# STM32G553 register map
File version: 2.0.0
CPU: CM33 r0p4, little endian, MPU, FPU, 4 interrupt priority bits
Registers are 32-bit, read-write, reset 0x0 unless marked. A register's access mark holds for its fields unless they carry their own. Offsets are from the block's base; [hi:lo] are bit positions.

## PKA — PKA register blank and RAM
Base 0x46008000
Same registers: PKA_S 0x56008000
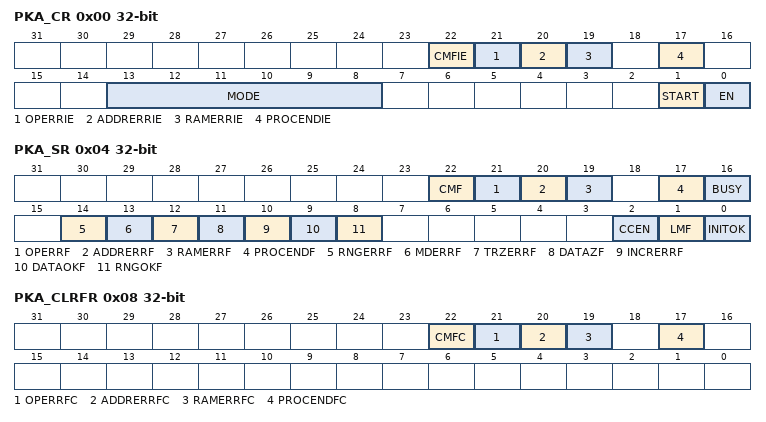
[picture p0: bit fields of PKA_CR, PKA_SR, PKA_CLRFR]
0x00 PKA_CR — PKA control register
  [22] CMFIE — Chaining mode flags interrupt enable
    0=No interrupt is generated when any flag in bits 8 to 15 is set in PKA_SR; 1=An interrupt is generated when any flag in bits 8 to 15 is set in PKA_SR
  [21] OPERRIE — Operation error interrupt enable
    0=No interrupt is generated when OPERRF flag is set in PKA_SR; 1=An interrupt is generated when OPERRF flag is set in PKA_SR
  [20] ADDRERRIE — Address error interrupt enable
    0=No interrupt is generated when ADDRERRF flag is set in PKA_SR; 1=An interrupt is generated when ADDRERRF flag is set in PKA_SR
  [19] RAMERRIE — RAM error interrupt enable
    0=No interrupt is generated when RAMERRF flag is set in PKA_SR; 1=An interrupt is generated when RAMERRF flag is set in PKA_SR
  [17] PROCENDIE — End of operation interrupt enable
    0=No interrupt is generated when PROCENDF flag is set in PKA_SR; 1=An interrupt is generated when PROCENDF flag is set in PKA_SR
  [13:8] MODE — PKA operation code
    0=Montgomery parameter computation then modular exponentiation; 1=Montgomery parameter computation only; 2=Modular exponentiation only (Montgomery parameter must be loaded first); 3=Modular exponentiation (protected, used when manipulating secrets); 32=Montgomery parameter computation then ECC scalar multiplication (protected); 36=ECDSA sign (protected); 38=ECDSA verification; 40=Point on elliptic curve Fp check; 7=RSA CRT exponentiation; 8=Modular inversion; 9=Arithmetic addition; 10=Arithmetic subtraction; 11=Arithmetic multiplication; 12=Arithmetic comparison; 13=Modular reduction; 14=Modular addition; 15=Modular subtraction; 16=Montgomery multiplication; 35=ECC complete addition; 39=ECC double base ladder; 47=ECC projective to affine
  [1] START — start the operation
  [0] EN — PKA enable
    0=Disable PKA; 1=Enable PKA; PKA becomes functional when INITOK is set by hardware in PKA_SR
0x04 PKA_SR ro — PKA status register
  [22] CMF — Chaining mode flags
    0=No chaining mode events; 1=Ongoing chaining mode sequence triggered at least one flag status in bits 8 to 14 of this register
  [21] OPERRF — Operation error flag
    0=No event error; 1=An illegal or unknown operation has been selected in PKA_CR register
  [20] ADDRERRF — Address error flag
    0=No address error; 1=Address access is out of range (unmapped address)
  [19] RAMERRF — PKA RAM error flag
    0=No PKA RAM access error; 1=An AHB access to the PKA RAM occurred while the PKA core was computing and using its internal RAM (AHB PKA_RAM access are not allowed while PKA operation is in progress)
  [17] PROCENDF — PKA end of operation flag
    0=Operation in progress; 1=PKA operation is completed. This flag is set when the BUSY bit is deasserted.
  [16] BUSY — Busy flag
    0=No operation is in progress (default); 1=An operation is in progress
  [14] RNGERRF — RNG error flag
    0=No random number drawn from RNG, or generated ECC private key is NIST compliant; 1=Random number drawn from RNG did not pass NIST key pair generation by testing candidates equivalent algorithm (see FIPS 186-4 annex B.4.2). The last chaining operation must be restarted, otherwise the selected PKA operation remains unusable.
  [13] MDERRF — Mode error flag
    0=No mode error; 1=The value written in MODE[5:0] of PKA_CR registers is different from the expected value corresponding to the CCOP mode selected in the CCB peripheral. Refer to Section30.4.7 for details.
  [12] TRZERRF — Trailing zeroes error flag
    0=No trailing 0s error; 1=Clear-text coming from CPU, or decrypted data coming from SAES does not have the required trailing 0s
  [11] DATAZF — Data zeroed error flag
  [10] INCRERRF — Increment error flag
    0=No increment error; 1=During the reading or writing of protected parameters from or to the PKA RAM, the application did not properly incremented the address. Refer to Section30.4.7 for details.
  [9] DATAOKF — Data OK flag
    0=Data not OK (if applicable), otherwise no event; 1=Sequential writes or reads to or from the PKA RAM successfully transfered the expected amount of data from or to SAES. Alternatively, the CPU wrote the correct amount of data in the PKA RAM. Refer to Section30.4.7 for details.
  [8] RNGOKF — RNG OK flag
    0=Random number not OK (if applicable). No event otherwise.; 1=Sequential writes to PKA RAM successfully transfered the expected amount of random data from the RNG. Refer to Section30.4.7 for details.
  [2] CCEN — Coupling and chaining mode enable
    0=Access to PKA RAM and programming of PKA_CR has no extra limitation; 1=The PKA RAM is write-only until START is set (it is no access then), and the MODE[5:0] value written in PKA_CR must correspond to the CCOP mode selected in the CCB peripheral. The application must also follow the coupling and chaining sequences described in Section30.4.7.
  [1] LMF — Limited mode flag
    0=All values documented in MODE[5:0] bit field can be used; 1=Only ECDSA verification (MODE[5:0] = 0x26) is supported by the PKA
  [0] INITOK — PKA initialization OK
    0=PKA is not initialized correctly. START bit cannot be set.; 1=PKA is initialized correctly and can be used normally
0x08 PKA_CLRFR wo — PKA clear flag register
  [22] CMFC — Clear chaining mode flag
    0=No action; 1=Clear the CMF flag and the chaining mode status bits in 8 to 15 in PKA_SR
  [21] OPERRFC — Clear operation error flag
    0=No action; 1=Clear the OPERRF flag in PKA_SR
  [20] ADDRERRFC — Clear address error flag
    0=No action; 1=Clear the ADDRERRF flag in PKA_SR
  [19] RAMERRFC — Clear PKA RAM error flag
    0=No action; 1=Clear the RAMERRF flag in PKA_SR
  [17] PROCENDFC — Clear PKA end of operation flag
    0=No action; 1=Clear the PROCENDF flag in PKA_SR
